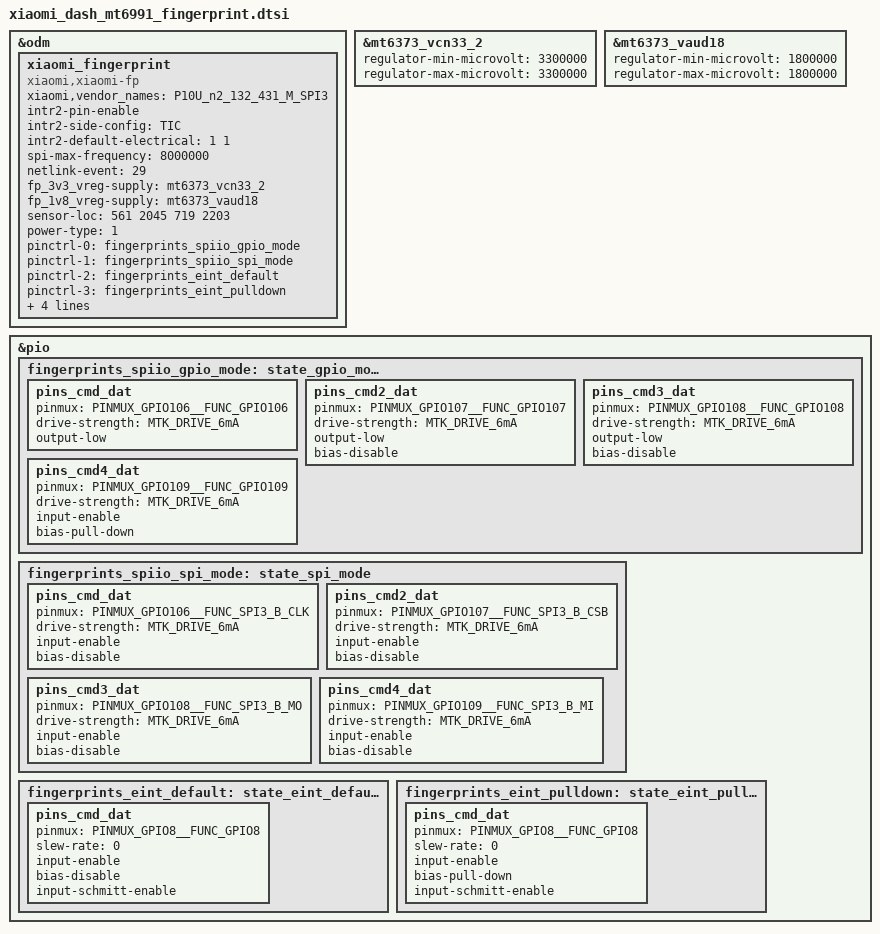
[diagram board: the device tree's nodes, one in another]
// SPDX-License-Identifier: (GPL-2.0 OR MIT)
/*
 * Copyright (C) 2024 MediaTek Inc.
 */

/* fingerprint start */

&odm {
	xiaomi_fingerprint: xiaomi_fingerprint {
		compatible = "xiaomi,xiaomi-fp";
		xiaomi,vendor_names = "P10U_n2_132_431_M_SPI3";
		intr2-pin-enable;
		intr2-side-config = "TIC";
		intr2-default-electrical = <1 1>;
		spi-max-frequency = <8000000>;
		netlink-event = <29>;
		fp_3v3_vreg-supply = <&mt6373_vcn33_2>;
		fp_1v8_vreg-supply = <&mt6373_vaud18>;
		sensor-loc = <561 2045 719 2203>;
		power-type = <1>;
		pinctrl-names = "spiio_gpio_mode", "spiio_spi_mode", "eint_default", "eint_pulldown";
		pinctrl-0 = <&fingerprints_spiio_gpio_mode>;
		pinctrl-1 = <&fingerprints_spiio_spi_mode>;
		pinctrl-2 = <&fingerprints_eint_default>;
		pinctrl-3 = <&fingerprints_eint_pulldown>;
		xiaomi,gpio_irq = <&pio 8 0>;
		xiaomi,gpio_ipc = <&pio 8 0>;
		interrupt-parent = <&pio>;
		interrupts = <8 IRQ_TYPE_EDGE_RISING 8 0>;
		status = "okay";
	};
};

&mt6373_vcn33_2 {
	regulator-min-microvolt = <3300000>;
	regulator-max-microvolt = <3300000>;
};

&mt6373_vaud18 {
	regulator-min-microvolt = <1800000>;
	regulator-max-microvolt = <1800000>;
};

&pio {
	fingerprints_spiio_gpio_mode: state_gpio_mode {
		pins_cmd_dat {
			pinmux = <PINMUX_GPIO106__FUNC_GPIO106>;
			drive-strength = <MTK_DRIVE_6mA>;
			output-low;
		};
		pins_cmd2_dat {
			pinmux = <PINMUX_GPIO107__FUNC_GPIO107>;
			drive-strength = <MTK_DRIVE_6mA>;
			output-low;
			bias-disable;
		};
		pins_cmd3_dat {
			pinmux = <PINMUX_GPIO108__FUNC_GPIO108>;
			drive-strength = <MTK_DRIVE_6mA>;
			output-low;
			bias-disable;
		};
		pins_cmd4_dat {
			pinmux = <PINMUX_GPIO109__FUNC_GPIO109>;
			drive-strength = <MTK_DRIVE_6mA>;
			input-enable;
			bias-pull-down;
		};
	};
	fingerprints_spiio_spi_mode: state_spi_mode {
		pins_cmd_dat {
			pinmux = <PINMUX_GPIO106__FUNC_SPI3_B_CLK>;
			drive-strength = <MTK_DRIVE_6mA>;
			input-enable;
			bias-disable;
		};
		pins_cmd2_dat {
			pinmux = <PINMUX_GPIO107__FUNC_SPI3_B_CSB>;
			drive-strength = <MTK_DRIVE_6mA>;
			input-enable;
			bias-disable;
		};
		pins_cmd3_dat {
			pinmux = <PINMUX_GPIO108__FUNC_SPI3_B_MO>;
			drive-strength = <MTK_DRIVE_6mA>;
			input-enable;
			bias-disable;
		};
		pins_cmd4_dat {
			pinmux = <PINMUX_GPIO109__FUNC_SPI3_B_MI>;
			drive-strength = <MTK_DRIVE_6mA>;
			input-enable;
			bias-disable;
		};
	};

	fingerprints_eint_default: state_eint_default {
		pins_cmd_dat {
			pinmux = <PINMUX_GPIO8__FUNC_GPIO8>;
			slew-rate = <0>;
			input-enable;
			bias-disable;
			input-schmitt-enable;
		};
	};
	fingerprints_eint_pulldown: state_eint_pulldown {
		pins_cmd_dat {
			pinmux = <PINMUX_GPIO8__FUNC_GPIO8>;
			slew-rate = <0>;
			input-enable;
			bias-pull-down;
			input-schmitt-enable;
		};
	};
};

/* fingerprint end */
